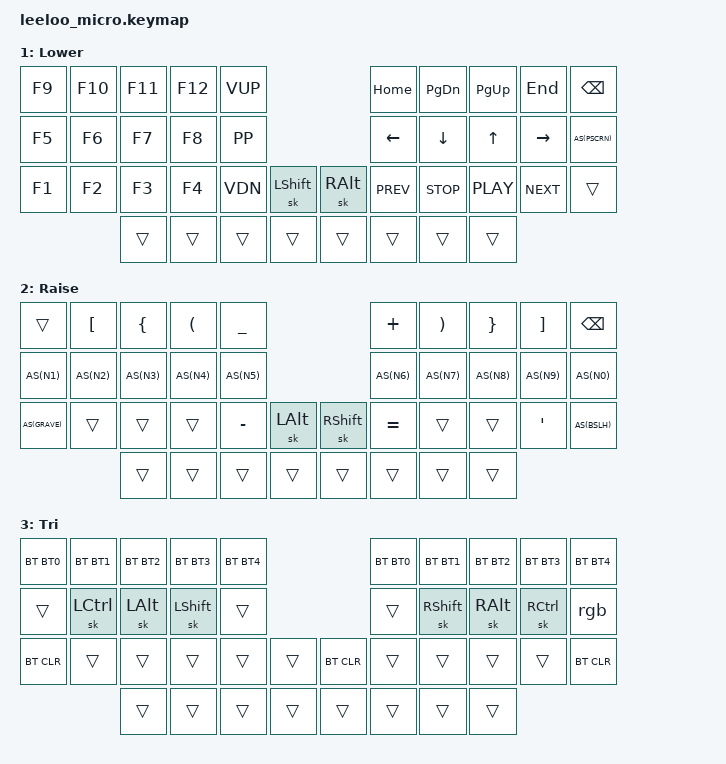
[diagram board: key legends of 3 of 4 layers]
/*
 * Copyright (c) 2023 The ZMK Contributors
 * SPDX-License-Identifier: MIT
 */

#include <behaviors.dtsi>
#include <dt-bindings/zmk/outputs.h>
#include <dt-bindings/zmk/keys.h>
#include <dt-bindings/zmk/bt.h>
#include <dt-bindings/zmk/rgb.h>

// Layers
#define ML    0       // Main
#define LL    1       // Lower
#define RL    2       // Raise
#define TL    3       // Tri

// Short versions
#define BT0         BT_SEL 0
#define BT1         BT_SEL 1
#define BT2         BT_SEL 2
#define BT3         BT_SEL 3
#define BT4         BT_SEL 4

#define BOOTLDR     &bootloader

#define VUP   C_VOL_UP
#define VDN   C_VOL_DN
#define PP    C_PP

#define RGBTOG  &rgb
#define RGBHUI  &rgb_ug RGB_HUI
#define RGBHUD  &rgb_ug RGB_HUD
#define RGBSAI  &rgb_ug RGB_SAI
#define RGBSAD  &rgb_ug RGB_SAD
#define RGBBRI  &rgb_ug RGB_BRI
#define RGBBRD  &rgb_ug RGB_BRD
#define RGBEFF  &rgb_ug RGB_EFF
#define RGBEFR  &rgb_ug RGB_EFR
#define RGBCUS  &rgb_ug RGB_COLOR_HSB(19, 98, 69)

// Thumb macro
#define TM(K) &mt LGUI K

// Auto shift
#define AS(K) &as LS(K) K

// Home row
#define LHR(K11,K12,K13) &hml LCTRL K11 &hml LALT K12 &hml LSHFT K13
#define RHR(K16,K17,K18) &hmr RSHFT K16 &hmr RALT K17 &hmr RCTRL K18

nice_view_spi: &spi0 {
    cs-gpios = <&pro_micro 4 GPIO_ACTIVE_HIGH>;
};


/ {
    conditional_layers {
        compatible = "zmk,conditional-layers";
        tri_layer {
            if-layers = <LL RL>;
            then-layer = <TL>;
        };
    };

    combos {
        compatible = "zmk,combos";

        combo_tab {
            timeout-ms = <30>;
            require-prior-idle-ms = <150>;
            key-positions = <0 1>;
            layers = <ML>;
            bindings = <&kp TAB>;
        };
        
        combo_grave {
            timeout-ms = <30>;
            require-prior-idle-ms = <150>;
            key-positions = <20 21>;
            layers = <ML>;
            bindings = <&kp GRAVE>;
        };
        
        combo_sqt {
            timeout-ms = <30>;
            key-positions = <31 30>;
            layers = <ML>;
            bindings = <&kp SQT>;
        };
    };

    behaviors {
        mt: mod_tap {
            compatible = "zmk,behavior-hold-tap";
            #binding-cells = <2>;
            flavor = "balanced";
            require-prior-idle-ms = <120>;
            tapping-term-ms = <280>;
            bindings = <&kp>, <&kp>;
            hold-trigger-on-release;
        };

        as: auto_shift {
            compatible = "zmk,behavior-hold-tap";
            #binding-cells = <2>;
            tapping-term-ms = <145>;
            quick-tap-ms = <0>;
            flavor = "tap-preferred";
            bindings = <&kp>, <&kp>;
        };

        hml: home_row_mod_left {
            compatible = "zmk,behavior-hold-tap";
            #binding-cells = <2>;
            flavor = "balanced";
            require-prior-idle-ms = <150>;
            tapping-term-ms = <280>;
            quick-tap-ms = <175>;
            bindings = <&kp>, <&kp>;
            hold-trigger-key-positions = <5 6 7 8 9 15 16 17 18 19 26 27 28 29 30 31 36 37 39>;
            hold-trigger-on-release;
        };

        hmr: home_row_mod_right {
            compatible = "zmk,behavior-hold-tap";
            #binding-cells = <2>;
            flavor = "balanced";
            require-prior-idle-ms = <150>;
            tapping-term-ms = <280>;
            quick-tap-ms = <175>;
            bindings = <&kp>, <&kp>;
            hold-trigger-key-positions = <0 1 2 3 4 10 11 12 13 14 20 21 22 23 24 25 32 34 35>;
            hold-trigger-on-release;
        };
        
        td_lshft: tap_dance_left_shift {
            compatible = "zmk,behavior-tap-dance";
            #binding-cells = <0>;
            tapping-term-ms = <150>;
            bindings = <&kp LSHFT>, <&kp CAPS>;
        };
        
        td_ll: tap_dance_lower_layer {
            compatible = "zmk,behavior-tap-dance";
            #binding-cells = <0>;
            tapping-term-ms = <150>;
            bindings = <&mo LL>, <&sl LL>;
        };
        
        td_rl: tap_dance_raise_layer {
            compatible = "zmk,behavior-tap-dance";
            #binding-cells = <0>;
            tapping-term-ms = <150>;
            bindings = <&mo RL>, <&sl RL>;
        };

        rgb: rgb_custom {
          compatible = "zmk,behavior-macro";
          #binding-cells = <0>;
          bindings = <&rgb_ug RGB_TOG RGBCUS>;
        };
    };

    keymap {
        compatible = "zmk,keymap";
//layer 0 (ML)
        base_layer {
            display-name = " LINUX";
            bindings = <
//╭──────────┬──────────┬──────────┬───────────┬───────────╮                           ╭───────────┬───────────┬──────────┬──────────┬──────────╮
//│   Q      │   W      │   E      │   R       │   T       │                           │   Y       │   U       │   I      │   O      │   P      │
  &kp Q      &kp W      &kp E      &kp R       &kp T                                   &kp Y       &kp U       &kp I      &kp O      &kp P
//├──────────┼──────────┼──────────┼───────────┼───────────┤                           ├───────────┼───────────┼──────────┼──────────┼──────────┤
//│   A      │   S      │   D      │   F       │   G       │                           │   H       │   J       │   K      │   L      │ ; :      │
  &kp A      LHR(S,         D,         F)      &kp G                                   &kp H       RHR(J,          K,         L)     AS(SEMI)
//├──────────┼──────────┼──────────┼───────────┼───────────┼───────────╮   ╭───────────┼───────────┼───────────┼──────────┼──────────┼──────────┤
//│   Z      │   X      │   C      │   V       │   B       │           |   |           │   N       │   M       │ , <      │ . >      │ / ?      │
  &kp Z      &kp X      &kp C      &kp V       &kp B       &kp LGUI        &kp DEL     &kp N       &kp M       &kp COMMA  &kp DOT    AS(FSLH)
//╰──────────┴──────────┼──────────┼───────────┼───────────┼───────────┤   ├───────────┼───────────┼───────────┼──────────┼──────────┴──────────╯
                        &sk LCTRL  &td_ll      &td_lshft   TM(ESC)         TM(RET)     &kp SPACE   &td_rl      &sk RCTRL
//                      ╰──────────┴───────────┴───────────┴───────────╯   ╰───────────┴───────────┴───────────┴──────────╯
          >;
        };
//layer 1 (LL)
        lower_layer {
            display-name = " Lower";
            bindings = <
//╭──────────┬──────────┬──────────┬───────────┬──────────╮                         ╭──────────┬───────────┬──────────┬──────────┬──────────╮
//│   F9     |   F10    |   F11    |   F12     |          │                         │   HOME   │  PG DOWN  │   PG UP  │   END    │   BSPC   │
  &kp F9     &kp F10    &kp F11    &kp F12     &kp VUP                              &kp HOME   &kp PG_DN   &kp PG_UP  &kp END    &kp BSPC
//├──────────┼──────────┼──────────┼───────────┼──────────┤                         ├──────────┼───────────┼──────────┼──────────┼──────────┤
//│   F5     │   F6     │   F7     │   F8      │          │                         │  <-      │  ⬇        │  ⬆       │   ->     │  PSCRN   │
  &kp F5     &kp F6     &kp F7     &kp F8      &kp PP                               &kp LEFT   &kp DOWN    &kp UP     &kp RIGHT  AS(PSCRN)
//├──────────┼──────────┼──────────┼───────────┼──────────┼──────────╮   ╭──────────┼──────────┼───────────┼──────────┼──────────┼──────────┤
//│   F1     │   F2     │   F3     │   F4      │          │   LSHFT  |   |   RALT   │          │           │          │          │          │
  &kp F1     &kp F2     &kp F3     &kp F4      &kp VDN    &sk LSHFT      &sk RALT   &kp C_PREV &kp C_STOP  &kp C_PLAY &kp C_NEXT &trans
//╰──────────┴──────────┼──────────┼───────────┼──────────┼──────────┤   ├──────────┼──────────┼───────────┼──────────┼──────────┴──────────╯
                        &trans     &trans      &trans     &trans         &trans     &trans     &trans      &trans
//                      ╰──────────┴───────────┴──────────┴──────────╯   ╰──────────┴──────────┴───────────┴──────────╯
            >;
        };
//layer 2 (RL)
        raise_layer {
            display-name = " Raise";
            bindings = <
//╭──────────┬──────────┬──────────┬───────────┬──────────╮                         ╭──────────┬───────────┬──────────┬──────────┬──────────╮
//│          │   LBKT   │   LBRC   │   LPAR    │   _      │                         │   +      │   RPAR    │   RBRC   │   RBKT   │   BSPC   │
  &trans     &kp LBKT   &kp LBRC   &kp LPAR    &kp UNDER                            &kp PLUS   &kp RPAR    &kp RBRC   &kp RBKT   &kp BSPC
//├──────────┼──────────┼──────────┼───────────┼──────────┤                         ├──────────┼───────────┼──────────┼──────────┼──────────┤
//│   1 !    │   2 @    │   3 #    │   4 $     │   5 %    │                         │   6 ^    │   7 &     │   8 *    │   9 LPAR │   0 RPAR │
  AS(N1)     AS(N2)     AS(N3)     AS(N4)      AS(N5)                               AS(N6)     AS(N7)      AS(N8)     AS(N9)     AS(N0)
//├──────────┼──────────┼──────────┼───────────┼──────────┼──────────╮   ╭──────────┼──────────┼───────────┼──────────┼──────────┼──────────┤
//│          │          │          │           │  - _     │   LALT   |   |   RSHFT  │  = +     │           │          │   SQT    │  \ |     │
  AS(GRAVE)  &trans     &trans     &trans      &kp MINUS  &sk LALT       &sk RSHFT  &kp EQUAL  &trans      &trans     &kp SQT    AS(BSLH)
//╰──────────┴──────────┼──────────┼───────────┼──────────┼──────────┤   ├──────────┼──────────┼───────────┼──────────┼──────────┴──────────╯
                        &trans     &trans      &trans     &trans         &trans     &trans     &trans      &trans
//                      ╰──────────┴───────────┴──────────┴──────────╯   ╰──────────┴──────────┴───────────┴──────────╯
            >;
        };
//layer 3 (TL)
        tri_layer {
            display-name = " Tri";
            bindings = <
//╭──────────┬──────────┬──────────┬───────────┬──────────╮                         ╭──────────┬───────────┬──────────┬──────────┬──────────╮
//│          |          |          |           |          │                         │          │           │          │          │          │
  &bt BT0    &bt BT1    &bt BT2    &bt BT3     &bt BT4                              &bt BT0    &bt BT1    &bt BT2    &bt BT3     &bt BT4
//├──────────┼──────────┼──────────┼───────────┼──────────┤                         ├──────────┼───────────┼──────────┼──────────┼──────────┤
//│          │   LCTRL  │   LALT   │   LSHFT   │          │                         │          │   RSHFT   │   RALT   │   RCTRL  │          │
  &trans     &sk LCTRL  &sk LALT   &sk LSHFT   &trans                               &trans     &sk RSHFT   &sk RALT   &sk RCTRL  RGBTOG
//├──────────┼──────────┼──────────┼───────────┼──────────┼──────────╮   ╭──────────┼──────────┼───────────┼──────────┼──────────┼──────────┤
//│   BT CLR │          │          │           │          │          |   |          │          │           │          │          │   BT_CLR │
  &bt BT_CLR &trans     &trans     &trans      &trans     &trans         &bt BT_CLR &trans     &trans     &trans      &trans     &bt BT_CLR
//╰──────────┴──────────┼──────────┼───────────┼──────────┼──────────┤   ├──────────┼──────────┼───────────┼──────────┼──────────┴──────────╯
                        &trans     &trans      &trans     &trans         &trans     &trans     &trans      &trans
//                      ╰──────────┴───────────┴──────────┴──────────╯   ╰──────────┴──────────┴───────────┴──────────╯
            >;
        };
    };
};
